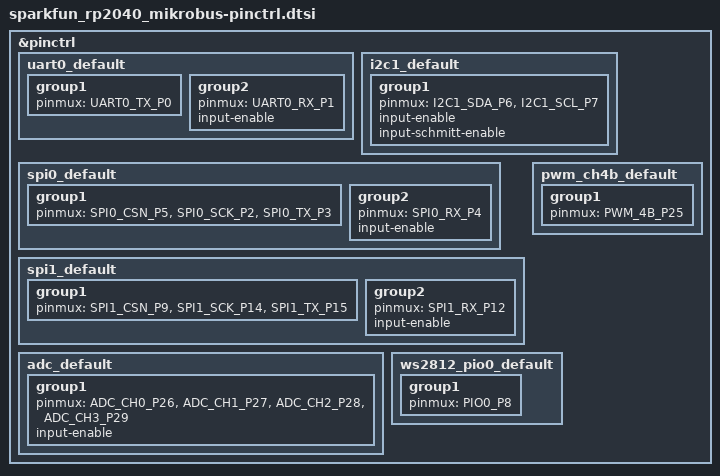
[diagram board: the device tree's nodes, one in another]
/*
 * SPDX-FileCopyrightText: Copyright (c) 2026 Navimatix GmbH
 * SPDX-FileCopyrightText: Copyright (c) 2026 TiaC Systems
 * SPDX-License-Identifier: Apache-2.0
 */

&pinctrl {
	uart0_default: uart0_default {
		group1 {
			pinmux = <UART0_TX_P0>;
		};

		group2 {
			pinmux = <UART0_RX_P1>;
			input-enable;
		};
	};

	i2c1_default: i2c1_default {
		group1 {
			pinmux = <I2C1_SDA_P6>, <I2C1_SCL_P7>;
			input-enable;
			input-schmitt-enable;
		};
	};

	spi0_default: spi0_default {
		group1 {
			pinmux = <SPI0_CSN_P5>, <SPI0_SCK_P2>, <SPI0_TX_P3>;
		};

		group2 {
			pinmux = <SPI0_RX_P4>;
			input-enable;
		};
	};

	spi1_default: spi1_default {
		group1 {
			pinmux = <SPI1_CSN_P9>, <SPI1_SCK_P14>, <SPI1_TX_P15>;
		};

		group2 {
			pinmux = <SPI1_RX_P12>;
			input-enable;
		};
	};

	pwm_ch4b_default: pwm_ch4b_default {
		group1 {
			pinmux = <PWM_4B_P25>;
		};
	};

	adc_default: adc_default {
		group1 {
			pinmux = <ADC_CH0_P26>, <ADC_CH1_P27>, <ADC_CH2_P28>, <ADC_CH3_P29>;
			input-enable;
		};
	};

	ws2812_pio0_default: ws2812_pio0_default {
		group1 {
			pinmux = <PIO0_P8>;
		};
	};
};
